AUTOSAR XML
package /AbsSystem
  sender receiver interface WheelSpeedIf
    data OmegaRadS
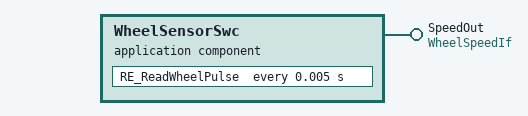
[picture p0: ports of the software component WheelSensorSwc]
  application sw component type WheelSensorSwc
    provide port SpeedOut: provided-interface=WheelSpeedIf
    behavior WheelSensor_IB
      runnable RE_ReadWheelPulse: execution-time-wcet=0.0008
      timing event TE_5ms: start-on-event=RE_ReadWheelPulse, period=0.005
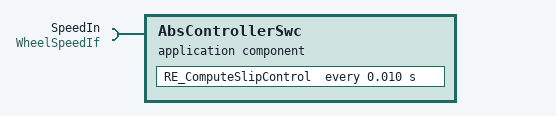
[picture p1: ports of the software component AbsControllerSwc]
  application sw component type AbsControllerSwc
    require port SpeedIn: required-interface=WheelSpeedIf
    behavior AbsController_IB
      runnable RE_ComputeSlipControl: execution-time-wcet=0.0022
      timing event TE_10ms: start-on-event=RE_ComputeSlipControl, period=0.010
  composition sw component type AbsTopComposition
    component WheelSensor: type=WheelSensorSwc
    component AbsCtrl: type=AbsControllerSwc
    connect {context-component=WheelSensor, target-p-port=SpeedOut} -> {context-component=AbsCtrl, target-r-port=SpeedIn}
